# D2522AA register map
Vendor: Dialog; Series: D2522AA; File version: 1.2
CPU: CM0 r1p0, little endian, MPU, FPU, 3 interrupt priority bits
Registers are 32-bit, read-write, reset 0x0 unless marked. A register's access mark holds for its fields unless they carry their own. Offsets are from the block's base; [hi:lo] are bit positions.

## CHARGER (part 1 of 2) — CHARGER registers
Base 0x50040400
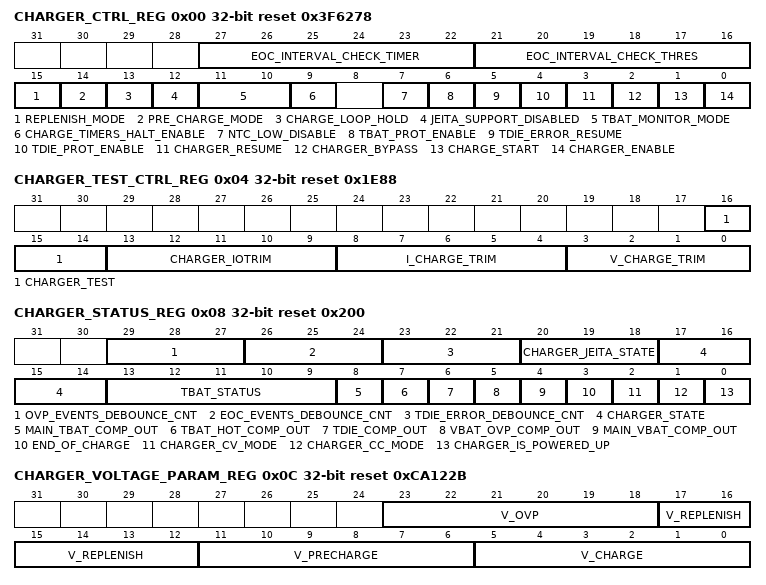
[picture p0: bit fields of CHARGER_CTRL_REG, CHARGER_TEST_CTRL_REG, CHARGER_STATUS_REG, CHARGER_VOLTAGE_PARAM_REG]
0x00 CHARGER_CTRL_REG reset 0x3F6278 — Charger main control register
  [27:22] EOC_INTERVAL_CHECK_TIMER ro — The specific bit-field determines the current state of the timer used to periodically check the End-of-Charge signal, as soon as the Charger's FSM is either in CC_CHARGE or CV_CHARGE state. Thus, as soon as the Charger's FSM enters the CC_CHARGE state: - The timer starts increasing when a positive edge detection on End-of-Charge signal occurs. - It keeps increasing until reaching the programmed EOC_INTERVAL_CHECK_THRES value, if and only if there is no detection of a negative edge on End-of-Charge signal. If this happens, the timer resets and starts over with a new End-of-Charge positive edge. - The timer also resets after having reached its programmed threshold or when the Charger's FSM next state is END_OF_CHARGE. This happens only after having found End-of-Charge signal asserted for 4 consecutive checks and provided that the specific signal has not de-asserted during the timer's interval. Note: It must be noted that out of these two states, the specific timer is kept to zero. It is also noted that this timer runs at the 1Mhz clock of the Charger's block and its value always ranges from 0 to the EOC_INTERVAL_CHECK_THRES value set in the respective bit-field of CHARGER_CTRL_REG.
  [21:16] EOC_INTERVAL_CHECK_THRES — This bit-field determines the periodic interval of checking the End-of-Charge signal, when the Charger's FSM is either in CC_CHARGE or in CV_CHARGE state. To implement this, a dedicated timer has been used, counting from zero up to the value programmed into this bit-field (see also EOC_INTERVAL_CHECK_TIMER field's description). As soon as this timer reaches the programmed value, the End-of-Charge signal is sampled and depending on its status (high or low), another counter, keeping the number of consecutive End-of-Charge events, is increased or not. See also the description of the EOC_DEBOUNCE_CNT bit-field of CHARGER_STATUS_REG, for this counter. Note: The specific bit-field should always be programmed to a non-zero value.
  [15] REPLENISH_MODE — When this bit-field is set and the Charger's FSM is in the BYPASSED state (thus, in Bypass mode), the internal multiplexer inside the digital part of the charger selects the Replenish, instead of the Pre-charge setting to be driven to the main Vbat comparator of the Charger's analogue circuitry. By this way, SW can read the respective analogue comparator's output in CHARGER_STATUS_REG (bit-field MAIN_VBAT_COMP_OUT), after the battery's volrtage has reached the End-of-Charge level, and determine if the battery voltage has dropped below the Replenish level, re-starting the battery charging accordingly. Note: When the Charger's FSM is active and operational, this bit-field is don't care and the FSM determines which level (Pre-charge or Replenish) will be selected and driven to the analogue, depending on the current state. It is also noted that the supported Pre-charge and Replenish levels can be viewed in the respective bit-fields defined in CHARGER_VOLTAGE_PARAM_REG register.
  [14] PRE_CHARGE_MODE — When set, this bit-field enables a signal of the same name with the bit-field, driven from the Charger's digital part towards the analogue circuitry, in order to determine the current in Pre-Charge mode. If the Charger's FSM is active and operational, the specific bit-field is don't care. Hence, it is considered only when the Charger's FSM has reached the BYPASSED state (thus, in Bypass mode). With the Charger's FSM being bypassed, SW should take over control and set the specific bit-field, in order to deliver the Pre-Charge instead of the normal Charge current to the Charger's analogue circuitry, during the Pre-Charge phase. Note: See also the description of CHARGER_CURRENT_PARAM_REG register for the Pre-Charge and normal Charge current levels supported.
  [13] CHARGE_LOOP_HOLD — When set, this bit-field disables charging, provided that the Charger's FSM has switched to the BYPASSED state. This is possible only by setting the CHARGER_BYPASS bit-field of this register. Thus, as soon as the Charger's FSM is bypassed, the respective signal driven by the FSM is overruled by this bit-field, making the analogue part of the Charger controllable also in this mode. If the Charger's FSM is not bypassed, this bit-field is don't care.
  [12] JEITA_SUPPORT_DISABLED — 0 = Charger's JEITA FSM monitoring the battery temperature checks also if battery temperature is in the Warm or Cool zones. In that case, it updates accordingly all the Charger's voltage levels (Charge, Pre-Charge, Replenish and OVP) programmed in CHARGER_VOLTAGE_PARAM_REG, as well as the charge and pre-charge current settings of CHARGER_CURRENT_PARAM_REG, depending on the temperature zone determined by the analogue circuitry of the Charger (see also the JEITA registers of the Charger's register file for the Voltage/Current levels in Warm and Cool temperature zones). 1 = Charger's JEITA FSM monitoring the battery temperature checks only if battery temperature is either in the Hot or Cold zones. In that case, it notifies the main Charger FSM to stop charging automatically, when in Hot zone. The same will happen also for the case of Cold, unless the NTC_LOW_DISABLE bit-field of CHARGER_CTRL_REG is set. Note : It is not recommended to have the specific bit-field kept to '0' (and thus the JEITA support enabled), if at the same time the bit-field TBAT_PROT_ENABLE of the same register is also '0'. Thus, JEITA support should be coupled with the Battery's temperature protection.
  [11:10] TBAT_MONITOR_MODE — Battery temperature pack monitoring modes, according to the following encoding: 00 = Battery temperature state checked and updated once, as soon as the charger is powered-up and settled. 01 = Battery temperature state checked periodically, depeding on TBAT_MON_TIMER_REG.TBAT_MON_INTERVAL and provided that Charger has been powered-up and charger's FSM is enabled. 10 = Battery temperature state checked periodically depending on TBAT_MON_TIMER_REG.TBAT_MON_INTERVAL, provided that Charger is powered-up and regardless if the Charger's FSM is enabled or not. Hence, this mode can be effective regardless of the state of CHARGE_START bit-field of CHARGER_CTRL_REG. 11 = When selected, it freezes the Battery temperature monitor FSM, as soon as the latter reaches the CHECK_IDLE state (see also CHARGER_STATUS_REG.CHARGER_JEITA_STATE bit-field's description for the states of this FSM). In this mode, the monitoring of Battery temperature is possible only by checking the status of TBAT_HOT_COMP_OUT and MAIN_TBAT_COMP_OUT bit-fields of CHARGER_STATUS_REG, thus by letting SW take over monitoring. This setting may be used in conjunction with Bypass mode (by setting CHARGER_BYPASS of CHARGER_CTRL_REG), so that both charging and battery temperature status monitoring are controlled by SW.
  [9] CHARGE_TIMERS_HALT_ENABLE — 0 = Charge timeout timers continue running when charging is disabled because of a Die or of a Battery temperature error. 1 = Charge timeout timers are halted in case of a Die or of a Battery temperature error. In that case, the global charge timer is stopped as soon as the Charger's FSM moves to TDIE_PROT or TBAT_PROT state. Also, either the Pre-Charge, the CC_CHARGE or the CV_CHARGE timer is also stopped, depending on the charging state of the FSM when the Die/Battery temperature error has been detected.
  [7] NTC_LOW_DISABLE — 0 = Charging is disabled when the battery temperature is found to have reached the "COLD" region. Therefore, the Charger's FSM moves directly to "TBAT_PROT" error and generates an IRQ to notify the system accordingly, in case the respective IRQ mask bit of CHARGER_ERROR_IRQ_MASK_REG is set. Also, CHARGER_ERROR_IRQ_STATUS_REG. TBAT_ERROR_IRQ field is updated accordingly. 1 = Charging is allowed to continue, even when the battery temperature pack reaches the "COLD" region. Consequently, the FSM continues charging and no battery temperature error event is generated.
  [6] TBAT_PROT_ENABLE — 0 = Battery temperature protection disabled 1 = Battery temperature protection enabled. Charging will be stopped in case Battery temperature reaches "Hot" zone. It will also be disabled when reaching "Cold" zone, provided that CHARGER_CTRL_REG.NTC_LOW_DISABLE is not set. This is handled by the Charger's FSM, which moves directly to the respective error state (TBAT_PROT), also generating an Error IRQ if the respective IRQ mask bit is set (see also CHARGER_ERROR_IRQ_MASK_REG).
  [5] TDIE_ERROR_RESUME — 0 = FSM will not resume from a Die temperature error. Consequently, its state will be staying to "TDIE_PROT", for as long as this bit-field is kept low, regardless of the status of the die tempeture comparator. Also, disabling the specific bit-field will reset the Die temperature error debounce counter, when the Charger's FSM is in TDIE_PROT state (so when a Die temperature error has been already detected) and the specific counter will remain frozen to 0 until the TDIE_ERROR_RESUME bit-field is set (see also the TDIE_ERROR_DEBOUNCE_CNT bit-field of CHARGER_STATUS_REG). 1 = FSM will resume from a Die temperature error, as soon as the respective analogue compator confirms that die temperature is again below the maximum allowed level. It is noted that the maximum Die temperature level is programmable via the CHARGER_TEMPSET_PARAM_REG register's respective bit-field (T_DIE_MAX).
  [4] TDIE_PROT_ENABLE — 0 = Die temperature protection is disabled, thus charging will not be disabled by the Charger's FSM in case of a Die temperature error. 1 = Die temperature protection is enabled, thus the Charger's FSM will move to "TDIE_PROT" state, disabling charging at the same time. It is noted that the Die temperature error event will be logged in the respective status bit of CHARGER_IRQ_ERROR_STATUS_REG and an IRQ will be generated, if and only if the corresponding mask bit of CHARGER_IRQ_MASK_REG is set.
  [3] CHARGER_RESUME — 0 = Charger's FSM is not enable to resume from a charge timeout error or a Vbat OVP (Over-Voltage Protection) error. Consequently, FSM stays in "ERROR" state. 1 = Charger's FSM will resume from a charge timeout or from an OVP error, thus its state will move from "ERROR" to "DISABLED" state, so that the charge cycle starts-over. It is noted that in the case of a Vbat OVP error, the FSM will leave "ERROR" state, as soon as the Vbat comparator for the OVP level shows that Vbat is again OK (so lower than the OVP setting).
  [2] CHARGER_BYPASS — 0 = Charger's FSM is active and running, notifying SW upon switching between its states 1 = Charger's FSM is bypassed, so its state stays to "BYPASS", so SW should take over the monitoring of the battery voltage and control of the charger.
  [1] CHARGE_START — 0 = Charger's FSM is disabled, FSM stays at "DISABLED" state 1 = Charger's FSM is enabled, so FSM's state can move from DISABLED to the actual charge states, starting from "PRE_CHARGE".
  [0] CHARGER_ENABLE — 0 = Charger's analogue circuitry is powered-down 1 = Charger's analogue circuitry is being powered-up and will be available after a certain settling time (in ms). As soon as this bit-field is set, the Charger's FSM waits for this settling time, before proceeding into DISABLED state, where it checks the Vbat level, as well as the Die temperature and the Battery temperature states. This is mandatory, before the actual charging begins, so before the FSM moves to PRE_CHARGE state. It is finally noted that the settling time is configurable via CHARGER_PWR_UP_TIMER_REG, counting with the 1Khz clock.
0x04 CHARGER_TEST_CTRL_REG reset 0x1E88 — Charger test control register
  [16:14] CHARGER_TEST — The following analogue signals may be mapped onto P1_07 pin, according to the following encoding: 000: Normal mode (no test mode selected) 001: Vptat (temperature sensor output) [1.4V max] 010: Vbat_sense after divider [1.2V] 011: Current loop output [0 to v30] 100: Voltage loop output [0 to v30] 101: Iref for the CC loop 110: Icharge reduced by 20 111: Imeas from output device Note : To enable this mapping, TEST_CTRL2_REG.ANA_TESTMUX_CTRL should be set to either 4,6 or 8 and TEST_CTRL5_REG[0] should be set to '0'. Both these two registers reside in the GPIO module. It is also noted that the specific pin (P1_07) should be configured as analogue pin, by setting P1_07_MODE_REG[PID] = FUNC_ADC (see also the description of P0_00_MODE_REG in the GPIO block, again).
  [13:9] CHARGER_IOTRIM — do not change, for test purposes only
  [8:4] I_CHARGE_TRIM — do not change, for test purposes only
  [3:0] V_CHARGE_TRIM — do not change, for test purposes only
0x08 CHARGER_STATUS_REG reset 0x200 — Charger main status register
  [29:27] OVP_EVENTS_DEBOUNCE_CNT ro — The specific bit-field returns the consecutive number of times Vbat has exceeded the programmed Over-Voltage Protection (OVP) level. It is used to determine when the Charger's FSM will exit any of the charging states (PRE/CC/CV_CHARGE) and will switch to the ERROR state due to an OVP error. This will happen as soon as the respective counter of OVP events reaches or exceeds a fixed number (4), similar to the approach adopted in the End-of-Charge and Die Temperature debouncing mechanisms. The specific counter increases only while the Charger's FSM is in any of the three charging,states, the Vbat OVP interval check timer has reached the threshold set and when Vbat OVP comparator's output is asserted. Note 1 : By default, as soon as the counter reaches 4, the FSM will switch to the ERROR state and the counter will reset again. Thus, in that case the specific counter ranges from 0 to 4 and vice-versa. However, if the monitoring of Vbat OVP comparator's state is less frequent than 5 (4+1) times the CHARGER_OVP_COMP_TIMER_REG[OVP_INTERVAL_CHECK_THRES] and Vbat has exceeded the OVP voltage level based on the comparator's output signal, then this counter will exceed 4 and may overflow. This will not harm, however, the detection of the OVP event, as it only increases the number of OVP event occurrences by the debounce timer, until the OVP comparator timer's settling time has expired. Thus, the Charger FSM will again switch to ERROR when the counter has reached or exceeded 4 (bit [2] of OVP_EVENTS_DEBOUNCE_CNT is set) and the OVP comparator's timer has expired. Note 2: See also the OVP_INTERVAL_CHECK_TIMER, OVP_INTERVAL_CHECK_THRES of CHARGER_OVP_COMP_TIMER_REG, for the debouncing mechanism of the Vbat OVP comparator's output.
  [26:24] EOC_EVENTS_DEBOUNCE_CNT ro — The specific bit-field returns the number of times the End-of-Charge signal has been consecutively found to be high. It is used to determine when the Charger's FSM will switch from CV_CHARGE to END_OF_CHARGE state, implementing a debounce mechanism on End-of-Charge signal, coming from the analogue circuitry of the Charger towards the FSM. The specific counter, running with the Charger's 1Mhz clock: - Increases after detecting that the End-of-Charge signal is high when the respective interval for the End-of-Charge check expires. This actually happens after having detected a positive edge on End-of-Charge signal, since only after that is it possible for the interval timer to start ticking. - Resets to zero when End-of-Charge is seen low when the interval timer has expired or when an End-of-Charge negative edge is seen before the timer's expiration, starting-over. - Does not count if End-of-Charge signal is seen high and either the CV_MODE signal (also driven by the analogue circutry) or the End-of-Charge signal of the previous clock cycle is seen low. - Is reset when the Charger's FSM is not in either the CC_CHARGE or the CV_CHARGE state or after having reached "100"(4). This is the threshold after which the End-of-Charge signal is considered stable by the Charger's FSM, to switch to the END_OF_CHARGE state. Thus, in practice, the specific counter (and bit-field) ranges between 0 and 4. Note: See also the EOC_INTERVAL_CHECK_TIMER/THRES bit-fields of CHARGER_CTRL_REG.
  [23:21] TDIE_ERROR_DEBOUNCE_CNT ro — The specific bit-field returns the consecutive number of times the Die temperature is seen either above (for the case of an error) or below (for the case of recovering from an error) the set Die temperature level.This is performed by a counter, which is increased: - Each time the Die temperature comparator shows that Die temperature exceeds the set level, and while charging is active, provided that Die temperature protection is enabled. If, however, the CHARGER_CTRL_REG.TDIE_PROT_ENABLE bit-field is not set, the counter is reset and stays frozen to zero. - Each time the Die temperature comparator shows that Die temperature is again below the set level, and while the FSM is in the Die temperature protection error state (TDIE_PROT) and the TDIE_ERROR_RESUME bit-field of CHARGER_CTRL_REG is set. If the specific bit-field is not set, the debounce counter is reset to 0 and it is kept frozen until the FSM is again enabled to resume from Die temperature errors. If the Die temperature comparator of the Charger's analogue circuitry shows that temperature has exceeded the programmed level for four consecutive times and charging is active, the Charger's FSM considers this as a Die temperature error and moves to the TDIE_PROT state, resetting the timer at the same time and of course halting charging. To recover from this state and resume charging, the FSM needs to see that Die temperature is below the programmed level for four consecutive times, again, provided that the TDIE_ERROR_RESUME bit-field of CHARGER_CTRL_REG is set. As soon as this happens, the error counter is again reset and the Charger's FSM resumes, by moving to PRE_CHARGE state. Consequently, the counter's value always ranges from 0 to 4. Note: When the Charger's FSM is in BYPASSED state, then this bit-field is reset and kept frozen to zero. Consequently, the number of times Die temperature has exceeded the pre-programmed threshold should be determined by SW.
  [20:18] CHARGER_JEITA_STATE ro — Returns the state of the Charger's JEITA FSM. This FSM is used to update the state of the battery temperature pack, depending on the value programmed in CHARGER_CTRL_REG.TBAT_MONITOR_MODE bit-field. The encoding of the states is as follows: 0x0 = CHECK_IDLE 0x1 = CHECK_THOT 0x2 = CHECK_TCOLD 0x3 = CHECK_TWARM 0x4 = CHECK_TCOOL 0x5 = CHECK_TNORMAL 0x6 = UPDATE_TBAT The FSM initially is in CHECK_IDLE state and starts checking the battery's temperature by visiting the states that check for the respective temperature area (Hot, Cold, Warm, Cool, Normal), in this order. If the battery temperature is found to be in one of the aforementioned zones, it directly moves to UPDATE_TBAT state, to update the battery temperature's state and notify the main FSM of the Charger about the battery temperature status, before returning to the CHECK_IDLE state. A Charger State IRQ will also be generated upon refreshing the battery temperature status (see also the description of CHARGER_STATE_IRQ_MASK_REG register).
  [17:14] CHARGER_STATE ro — Indicating the state of the Charger's main FSM, based on the following encoding: 0x0 = POWER_UP (Charger's power-up not yet set) 0x1 = INIT (Charger is being power-up, FSM waiting for the analogue to settle) 0x2 = DISABLED (Charger powered-up but charging not yet started) 0x3 = PRE_CHARGE (Pre-Charge state) 0x4 = CC_CHARGE (Constant Current state) 0x5 = CV_CHARGE (Constant Voltage state) 0x6 = END_OF_CHARGE (End-of-Charge state) 0x7 = TDIE_PROT (Die temperature protection state, visited when Die temperature limit is exceeded) 0x8 = TBAT_PROT (Battery temperature protection state, visited when Battery temperature is either COLD or HOT) 0x9 = BYPASSED (Bypassed state, visited only when the FSM is bypassed and SW takes over control) 0xA = ERROR (Error state, visited when a charge time-out occurs or in the case of Vbat exceeding over-voltage level)
  [13:9] TBAT_STATUS ro — Battery pack temperature status, according to the following ("1-Hot"-like) encoding: 00001 : Battery temperature in COLD zone (default) 00010 : Battery temperature in COOL zone 00100 : Battery temperature in NORMAL zone (above COOL and below WARM zones) 01000 : Battery temperature in WARM zone 10000 : Battery temperature in HOT zone It is noted that, according to the JEITA standard (supported if the JEITA_SUPPORT_ENABLED bit-field of CHARGER_CTRL_REG is not set) , if the battery pack temperature is in the "HOT" zone, charging will always be stopped. The same will happen also for the case of the COLD zone, unless the "NTC_LOW_DISABLE" bit-field of CHARGER_CTRL_REG is set. In that case, charging will continue. It is finally noted that only the aforementioned values are available for this bit-field, since it is 1-Hot encoding based. Not more than 1 bit can be high at the same time, since this would mean that battery temperature is at two different temperature zones concurrently.
  [8] MAIN_TBAT_COMP_OUT ro — Returns the status of the main battery temperature comparator. This comparator by default checks if the battery temperature is in the Cold zone. However, if JEITA support is enabled and battery temperature is found to not be in either the Hot or the Cold zone, the same comparator is used to check for the Warm and Cool zones, as JEITA suggests. The specific bit-field is suggested to be used in bypass mode and when the JEITA support is disabled (so when the battery temperature is checked agains the Hot and the Cold zones). In that case, the comparator checks the battery temperature agains the Cold level and its status can be as follows: 0 = Battery temperature pack is found to be below the Cold level, so in the non-allowed Cold temperature zone. Thus, charging will be disabled, provided that the NTC_LOW_DISABLE bit-field of CHARGER_CTRL_REG is not set. 1 = Battery temperature pack is found to be above the non-allowed Cold temperature zone. Thus, charging will be continued, provided that battery temperature will not be in the Hot zone as well. When the Charger's main FSM is active and JEITA is enabled, the Charger's digital block takes over and controls the respective comparator's output.
  [7] TBAT_HOT_COMP_OUT ro — Returns the status of the battery temperature comparator dedicated to the Hot temperature zone. 0 = Battery temperature pack is found to be below the Hot zone 1 = Battery temperature pack is found to be in the non-allowed Hot temperature zone. Thus, charging will be disabled, provided that battery temperature protection is enabled.
  [6] TDIE_COMP_OUT ro — 0 = Die temperature is found to be below the programmed level, set in CHARGER_TEMPSET_PARAM_REG.TDIE_SET level (normal operation) 1 = Die temperature is found to be above the set level. Charging will be disabled if Die temperature protection is enabled and the Die temperature is found to be above the set level four consecutive times (see also TDIE_ERROR_DEBOUNCE_CNT bit-field). In that case, the Charger's FSM will also move the respective error state (TDIE_PROT) and an IRQ may be generated, if the respective mask bit of CHARGER_ERROR_IRQ_MASK_REG is set.
  [5] VBAT_OVP_COMP_OUT ro — 0 = Vbat has not exceeded the Over-Voltage Protection (OVP) voltage limit, according to the respective analogue comparator's output. 1 = Vbat is found to have exceeded the OVP voltage setting, thus charging should be disabled. The OVP voltage settings are defined in CHARGER_VOLTAGE_PARAM_REG.V_OVP (for the Normal battery temperature zone), as well as in CHARGER_JEITA_V_OVP_REG (for Cool and Warm temperature zones, to comply with JEITA).
  [4] MAIN_VBAT_COMP_OUT ro — This bit-field reflects the status of the main Vbat comparator residing in the analogue circuitry of the Charger. This comparator is used to check Vbat against either the Pre-Charge or the Replenish voltage level, depending on what is driven by the Charger's digital block. Thus, when the FSM is active, the comparator gets as reference the Replenish setting as soon as the FSM has reached the END_OF_CHARGE state. Otherwise,the Pre-Charge voltage setting is driven, including the Bypass mode. According to the above, the encoding is as follows for the case the comparator compares Vbat against the Pre-Charge level: 0 = Vbat has not exceeded the set Pre-Charge voltage level. 1 = Vbat has reached or exceeded the set Pre-Charge voltage level. For the case the comparator compares agains the Replenish level (when the FSM has reached the END_OF_CHARGE state, so when the charging has been completed), the encoding is as follows: 0 = Vbat has dropped below the set Replenish level, so charging will re-start and the FSM will move to the PRE_CHARGE state. 1 = Vbat is still greater or equal to the set Replenish level, thus charging remains in hold and the FSM in END_OF_CHARGE state.
  [3] END_OF_CHARGE ro — 0 = Actual charge current is above the current level programmed in I_END_OF_CHARGE field of CHARGER_CURRENT_PARAM_REG (or charger is off) 1 = Actual charge current is below the current level programmed in I_END_OF_CHARGE bit-field of CHARGER_CURRENT_PARAM_REG.
  [2] CHARGER_CV_MODE ro — 0 = Charger's voltage loop not in regulation (or Charger is off) 1 = Charger's Constant Voltage (CV) mode active, voltage loop in regulation
  [1] CHARGER_CC_MODE ro — 0 = Charger's Current loop not in regulation (or Charger is off) 1 = Charger's Constant Current (CC) mode active, current loop in regulation
  [0] CHARGER_IS_POWERED_UP ro — 0 = Charger is either off or it is being powered-on but the analogue ciruitry is not yet settled. The charger's main FSM is either in POWER_UP or INIT states. 1 = Charger is powered-up, so its analogue ciruitry should now be settled. The Charger's FSM has left both power-up states (POWER_UP, INIT), so charging can start.
0x0C CHARGER_VOLTAGE_PARAM_REG reset 0xCA122B — Charger voltage settings register
  [23:18] V_OVP — This bit-field determines the VBAT Over-voltage protection limit. This Over-voltage protection level is used by the Charger's analogue circuitry and specifically by a dedicated comparator, the output of which is sampled by the digital block of the Charger. As soon as VBAT is detected to have reached or exceeded this level, the Charger's FSM moves to ERROR state, interrupting charging. If the respective Error IRQ mask bit is set, an Error IRQ pulse will be also generated. Regarding the actual range of supported values for this bit-field, see the the description of V_CHARGE bit-field of this register.
  [17:12] V_REPLENISH — This bit-field determines the absolute value (in V) of the Replenish voltage threshold. As soon as charging has been completed and the Charger's FSM has reached the END_OF_CHARGE state, the respective analogue comparator of the Charger compares VBAT with the Replenish level. If VBAT is found to have dropped below this level, charging should start-over again and in that case, the FSM moves again to the PRE_CHARGE state. Regarding the supported Replenish voltage levels, see the description of V_CHARGE bit-field.
  [11:6] V_PRECHARGE — This bit-field determines the voltage level at which the battery is considered as Pre-charged and therefore the Charger's FSM should move to the CC_CHARGE state, entering the Constant Current charging phase. Regarding the supported Pre-Charge voltage levels, see also the description of V_CHARGE bit-field of this register.
  [5:0] V_CHARGE — This bit-field determines the charge voltage levels supported. The supported levels are determined according to the following encoding: 0 : 2.80V 1 : 2.85V 2 : 2.90V 3 : 2.95V 4 : 3.00V 5 : 3.05V 6 : 3.10V 7 : 3.15V 8 : 3.20V 9 : 3.25V 10 : 3.30V 11 : 3.35V 12 : 3.40V 13 : 3.45V 14 : 3.50V 15 : 3.55V 16 : 3.60V 17 : 3.65V 18 : 3.70V 19 : 3.75V 20 : 3.80V 21 : 3.82V 22 : 3.84V 23 : 3.86V 24 : 3.88V 25 : 3.90V 26 : 3.92V 27 : 3.94V 28 : 3.96V 29 : 3.98V 30 : 4.00V 31 : 4.02V 32 : 4.04V 33 : 4.06V 34 : 4.08V 35 : 4.10V 36 : 4.12V 37 : 4.14V 38 : 4.16V 39 : 4.18V 40 : 4.20V 41 : 4.22V 42 : 4.24V 43 : 4.26V 44 : 4.28V 45 : 4.30V 46 : 4.32V 47 : 4.34V 48 : 4.36V 49 : 4.38V 50 : 4.40V 51 : 4.42V 52 : 4.44V 53 : 4.46V 54 : 4.48V 55 : 4.50V 56 : 4.52V 57 : 4.54V 58 : 4.56V 59 : 4.58V 60 : 4.60V 61 : 4.70V 62 : 4.80V 63 : 4.90V* It has to be noted that the specific values correspond to the normal battery temperature zone. However, the specific register field may be updated by the JEITA FSM (which checks the battery temperature either once or periodically), in order to adapt the charge voltage to the battery temperature zone (see also CHARGER_CTRL_REG.TBAT_MONITOR_MODE field as well). This is valid also for the other three fields of the current register. Consequently, in that case the register returns the Charge voltage settings that abide to the JEITA requirements for the battery (either COOL, WARM or NORMAL). Note: Option "63" (4.90V) is not supported for V_CHARGE, V_PRECHARGE and V_REPLENISH bit-fields (and respective levels). It should be used only in the V_OVP bit-field, as the (maximum) Over-voltage protection level.
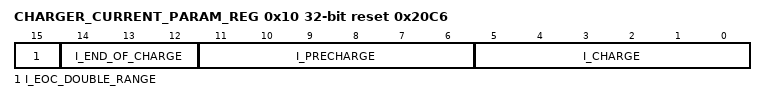
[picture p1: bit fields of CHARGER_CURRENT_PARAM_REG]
0x10 CHARGER_CURRENT_PARAM_REG reset 0x20C6 — Charger current settings register
  [15] I_EOC_DOUBLE_RANGE — When set, the specific bit-field enables the doubling of the (%) range of End-of-Charge current setting. Consequently, the default lower and upper limits of 6% of I_CHARGE (value 0x0 of I_END_OF_CHARGE bit-field) and 20% (value 0x7 of the same bit-field) are increased to 12% and 40% respectively, as soon as the I_EOC_DOUBLE_RANGE field is set.
  [14:12] I_END_OF_CHARGE — End-of-Charge current setting, ranging from 6%("000") to 20% ("111") of the charge current set, with a step size of 2%, as follows: 000 : 6% 001 : 8% 010 : 10% 011 : 12% 100 : 14% 101 : 16% 110 : 18% 111 : 20% Note: The aforementioned range of 6%-20% and the respective values of this bit-field are valid if the I_EOC_DOUBLE_RANGE field of this register is not set. Otherwise, the (%) range of Charge current determining the End-of-Charge current is doubled to 12%-40%, and consequently each of the values (0x0-0x7) listed above represents a doubled (%) percentage.
  [11:6] I_PRECHARGE — This bit-field determines the Pre-Charge current, in mA, ranging from 0.5 to 56mA, according to the following encoding: 0 : 0.5 mA 1 : 1 mA 2 : 1.5mA 3 : 2 mA 4 : 2.5mA 5 : 3 mA 6 : 3.5mA 7 : 4 mA 8 : 4.5mA 9 : 5 mA 10 : 5.5mA 11 : 6 mA 12 : 6.5mA 13 : 7 mA 14 : 7.5mA 15 : 8 mA 16 : 9 mA 17 : 10 mA 18 : 11 mA 19 : 12 mA 20 : 13 mA 21 : 14 mA 22 : 15 mA 23 : 16 mA 24 : 17 mA 25 : 18 mA 26 : 19 mA 27 : 20 mA 28 : 21 mA 29 : 22 mA 30 : 23 mA 31 : 24 mA 32 : 26 mA 33 : 28 mA 34 : 30 mA 35 : 32 mA 36 : 34 mA 37 : 36 mA 38 : 38 mA 39 : 40 mA 40 : 42 mA 41 : 44 mA 42 : 46 mA 43 : 48 mA 44 : 50 mA 45 : 52 mA 46 : 54 mA 47 : 56 mA 48 : 56 mA 49 : 56 mA 50 : 56 mA 51 : 56 mA 52 : 56 mA 53 : 56 mA 54 : 56 mA 55 : 56 mA 56 : 56 mA 57 : 56 mA 58 : 56 mA 59 : 56 mA 60 : 56 mA 61 : 56 mA 62 : 56 mA 63 : 56 mA
  [5:0] I_CHARGE — This bit-field determines the charge current range, in mA. The range is from 5mA to 560mA, according to the following encoding: 0 : 5 mA 1 : 10 mA 2 : 15 mA 3 : 20 mA 4 : 25 mA 5 : 30 mA 6 : 35 mA 7 : 40 mA 8 : 45 mA 9 : 50 mA 10 : 55 mA 11 : 60 mA 12 : 65 mA 13 : 70 mA 14 : 75 mA 15 : 80 mA 16 : 90 mA 17 : 100 mA 18 : 110 mA 19 : 120 mA 20 : 130 mA 21 : 140 mA 22 : 150 mA 23 : 160 mA 24 : 170 mA 25 : 180 mA 26 : 190 mA 27 : 200 mA 28 : 210 mA 29 : 220 mA 30 : 230 mA 31 : 240 mA 32 : 260 mA 33 : 280 mA 34 : 300 mA 35 : 320 mA 36 : 340 mA 37 : 360 mA 38 : 380 mA 39 : 400 mA 40 : 420 mA 41 : 440 mA 42 : 460 mA 43 : 480 mA 44 : 500 mA 45 : 520 mA 46 : 540 mA 47 : 560 mA 48 : 560 mA 49 : 560 mA 50 : 560 mA 51 : 560 mA 52 : 560 mA 53 : 560 mA 54 : 560 mA 55 : 560 mA 56 : 560 mA 57 : 560 mA 58 : 560 mA 59 : 560 mA 60 : 560 mA 61 : 560 mA 62 : 560 mA 63 : 560 mA Note: It has to be noted that the specific values correspond to the normal battery temperature zone. However, the specific register field may be updated by the JEITA FSM (which checks the battery temperature either once or periodically), in order to adapt the Charge current to the new battery temperature zone (see also CHARGER_CTRL_REG.TBAT_MONITOR_MODE field as well). This is valid also for the Pre-Charge current field of this register and provided that JEITA support is enabled in CHARGER_CTRL_REG. Consequently, in that case the register return the Charge current settings that abide to the JEITA requirements for the battery (either COOL, WARM or NORMAL).
